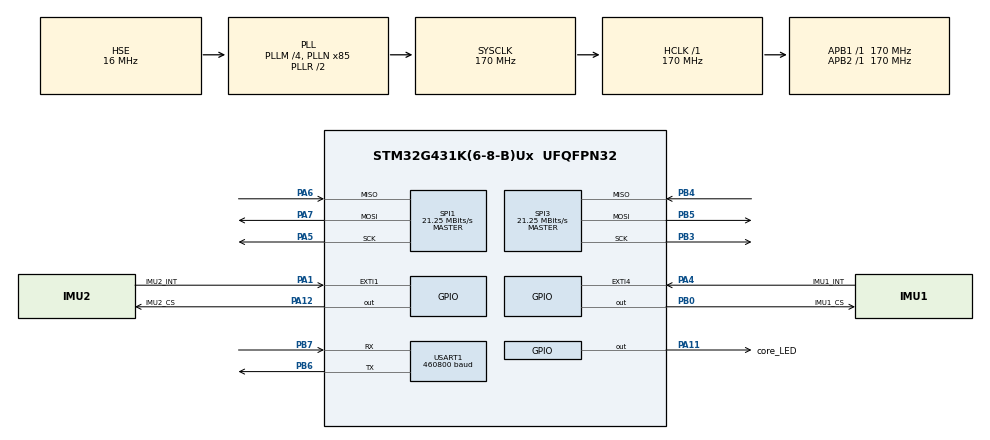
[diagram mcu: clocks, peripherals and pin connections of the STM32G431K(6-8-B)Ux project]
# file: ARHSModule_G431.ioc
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Dma.Request0=USART1_RX
Dma.Request1=USART1_TX
Dma.USART1_RX.0.Direction=DMA_PERIPH_TO_MEMORY
Dma.USART1_RX.0.EventEnable=DISABLE
Dma.USART1_RX.0.Instance=DMA1_Channel1
Dma.USART1_RX.0.MemDataAlignment=DMA_MDATAALIGN_BYTE
Dma.USART1_RX.0.MemInc=DMA_MINC_ENABLE
Dma.USART1_RX.0.Mode=DMA_NORMAL
Dma.USART1_RX.0.PeriphDataAlignment=DMA_PDATAALIGN_BYTE
Dma.USART1_RX.0.PeriphInc=DMA_PINC_DISABLE
Dma.USART1_RX.0.Polarity=HAL_DMAMUX_REQ_GEN_RISING
Dma.USART1_RX.0.Priority=DMA_PRIORITY_LOW
Dma.USART1_RX.0.RequestNumber=1
Dma.USART1_RX.0.SignalID=NONE
Dma.USART1_RX.0.SyncEnable=DISABLE
Dma.USART1_RX.0.SyncPolarity=HAL_DMAMUX_SYNC_NO_EVENT
Dma.USART1_RX.0.SyncRequestNumber=1
Dma.USART1_RX.0.SyncSignalID=NONE
Dma.USART1_TX.1.Direction=DMA_MEMORY_TO_PERIPH
Dma.USART1_TX.1.EventEnable=DISABLE
Dma.USART1_TX.1.Instance=DMA1_Channel2
Dma.USART1_TX.1.MemDataAlignment=DMA_MDATAALIGN_BYTE
Dma.USART1_TX.1.MemInc=DMA_MINC_ENABLE
Dma.USART1_TX.1.Mode=DMA_NORMAL
Dma.USART1_TX.1.PeriphDataAlignment=DMA_PDATAALIGN_BYTE
Dma.USART1_TX.1.PeriphInc=DMA_PINC_DISABLE
Dma.USART1_TX.1.Polarity=HAL_DMAMUX_REQ_GEN_RISING
Dma.USART1_TX.1.Priority=DMA_PRIORITY_HIGH
Dma.USART1_TX.1.RequestNumber=1
Dma.USART1_TX.1.SignalID=NONE
Dma.USART1_TX.1.SyncEnable=DISABLE
Dma.USART1_TX.1.SyncPolarity=HAL_DMAMUX_SYNC_NO_EVENT
Dma.USART1_TX.1.SyncRequestNumber=1
Dma.USART1_TX.1.SyncSignalID=NONE
Mcu.Family=STM32G4
Mcu.Name=STM32G431K(6-8-B)Ux
Mcu.Package=UFQFPN32
NVIC.DMA1_Channel1_IRQn=true\:5\:0\:true\:false\:true\:false\:true\:true
NVIC.DMA1_Channel2_IRQn=true\:5\:1\:true\:false\:true\:false\:true\:true
NVIC.EXTI4_IRQn=true\:0\:1\:false\:false\:true\:true\:true\:true
NVIC.PriorityGroup=NVIC_PRIORITYGROUP_3
NVIC.TIM1_UP_TIM16_IRQn=true\:0\:0\:false\:false\:true\:true\:true\:true
NVIC.USART1_IRQn=true\:3\:1\:true\:false\:true\:false\:true\:true
PA1.GPIO_Label=IMU2_INT
PA1.GPIO_PuPd=GPIO_PULLDOWN
PA1.Signal=GPXTI1
PA11.GPIO_Label=core_LED
PA11.GPIO_PuPd=GPIO_PULLUP
PA11.Signal=GPIO_Output
PA12.GPIO_Label=IMU2_CS
PA12.GPIO_PuPd=GPIO_NOPULL
PA12.PinState=GPIO_PIN_RESET
PA12.Signal=GPIO_Output
PA13.Mode=Serial_Wire
PA13.Signal=SYS_JTMS-SWDIO
PA14.Mode=Serial_Wire
PA14.Signal=SYS_JTCK-SWCLK
PA4.GPIO_Label=IMU1_INT
PA4.GPIO_PuPd=GPIO_PULLDOWN
PA4.Signal=GPXTI4
PA5.GPIO_Speed=GPIO_SPEED_FREQ_LOW
PA5.Mode=Full_Duplex_Master
PA5.Signal=SPI1_SCK
PA6.GPIO_Speed=GPIO_SPEED_FREQ_LOW
PA6.Mode=Full_Duplex_Master
PA6.Signal=SPI1_MISO
PA7.GPIO_Speed=GPIO_SPEED_FREQ_LOW
PA7.Mode=Full_Duplex_Master
PA7.Signal=SPI1_MOSI
PB0.GPIO_Label=IMU1_CS
PB0.GPIO_PuPd=GPIO_NOPULL
PB0.PinState=GPIO_PIN_RESET
PB0.Signal=GPIO_Output
PB3.GPIO_Speed=GPIO_SPEED_FREQ_VERY_HIGH
PB3.Mode=Full_Duplex_Master
PB3.Signal=SPI3_SCK
PB4.GPIO_Speed=GPIO_SPEED_FREQ_VERY_HIGH
PB4.Mode=Full_Duplex_Master
PB4.Signal=SPI3_MISO
PB5.GPIO_Speed=GPIO_SPEED_FREQ_VERY_HIGH
PB5.Mode=Full_Duplex_Master
PB5.Signal=SPI3_MOSI
PB6.Mode=Asynchronous
PB6.Signal=USART1_TX
PB7.Mode=Asynchronous
PB7.Signal=USART1_RX
PF0-OSC_IN.Mode=HSE-External-Oscillator
PF0-OSC_IN.Signal=RCC_OSC_IN
PF1-OSC_OUT.Mode=HSE-External-Oscillator
PF1-OSC_OUT.Signal=RCC_OSC_OUT
ProjectManager.HeapSize=0x2000
ProjectManager.StackSize=0x4000
ProjectManager.TargetToolchain=MDK-ARM V5.32
RCC.ADC12Freq_Value=170000000
RCC.AHBFreq_Value=170000000
RCC.APB1Freq_Value=170000000
RCC.APB1TimFreq_Value=170000000
RCC.APB2Freq_Value=170000000
RCC.APB2TimFreq_Value=170000000
RCC.CortexFreq_Value=170000000
RCC.EXTERNAL_CLOCK_VALUE=12288000
RCC.HCLKFreq_Value=170000000
RCC.HSE_VALUE=16000000
RCC.HSI48_VALUE=48000000
RCC.HSI_VALUE=16000000
RCC.LSE_VALUE=32768
RCC.PLLM=RCC_PLLM_DIV4
RCC.PLLN=85
RCC.PLLSourceVirtual=RCC_PLLSOURCE_HSE
RCC.SYSCLKFreq_VALUE=170000000
RCC.SYSCLKSource=RCC_SYSCLKSOURCE_PLLCLK
RCC.USBFreq_Value=170000000
RCC.VCOOutputFreq_Value=340000000
SPI1.BaudRatePrescaler=SPI_BAUDRATEPRESCALER_8
SPI1.CalculateBaudRate=21.25 MBits/s
SPI1.DataSize=SPI_DATASIZE_8BIT
SPI1.Direction=SPI_DIRECTION_2LINES
SPI1.Mode=SPI_MODE_MASTER
SPI1.NSSPMode=SPI_NSS_PULSE_DISABLE
SPI1.VirtualType=VM_MASTER
SPI3.BaudRatePrescaler=SPI_BAUDRATEPRESCALER_8
SPI3.CalculateBaudRate=21.25 MBits/s
SPI3.DataSize=SPI_DATASIZE_8BIT
SPI3.Direction=SPI_DIRECTION_2LINES
SPI3.Mode=SPI_MODE_MASTER
SPI3.NSSPMode=SPI_NSS_PULSE_DISABLE
SPI3.VirtualType=VM_MASTER
TIM1.PeriodNoDither=1000-1
TIM1.Prescaler=170-1
USART1.BaudRate=460800
USART1.VirtualMode-Asynchronous=VM_ASYNC
VP_SYS_VS_DBSignals.Mode=DisableDeadBatterySignals
VP_TIM1_VS_ClockSourceINT.Mode=Internal
board=custom

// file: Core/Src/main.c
/* USER CODE BEGIN Header */
/**
  ******************************************************************************
  * @file           : main.c
  * @brief          : Main program body
  ******************************************************************************
  * @attention
  *
  * Copyright (c) 2025 STMicroelectronics.
  * All rights reserved.
  *
  * This software is licensed under terms that can be found in the LICENSE file
  * in the root directory of this software component.
  * If no LICENSE file comes with this software, it is provided AS-IS.
  *
  ******************************************************************************
  */
/* USER CODE END Header */
#include "main.h"
#include "dma.h"
#include "spi.h"
#include "tim.h"
#include "usart.h"
#include "gpio.h"

/* USER CODE BEGIN Includes */
#include "delay.h"
#include "icm45686_task.h"
#include "angle.h"
/* USER CODE END Includes */

void SystemClock_Config(void);

int main(void)
{

  /* MCU Configuration--------------------------------------------------------*/

  /* Reset of all peripherals, Initializes the Flash interface and the Systick. */
  HAL_Init();

  /* Configure the system clock */
  SystemClock_Config();

  /* USER CODE BEGIN SysInit */
	delay_init(170);//基于内核时钟频率延时初始化
  /* USER CODE END SysInit */

  /* Initialize all configured peripherals */
  MX_GPIO_Init();
  MX_DMA_Init();
  MX_SPI1_Init();
  MX_SPI3_Init();
  MX_USART1_UART_Init();
  MX_TIM1_Init();
  /* USER CODE BEGIN 2 */
	LED(1);//点亮LED
	if(imu_init(&myIMU1) == INV_IMU_OK &&imu_init(&myIMU2) == INV_IMU_OK)
	{
		IMU_Calibration();//IMU静止状态下零漂矫正
		myIMU1.is_init_ok =1;
		myIMU2.is_init_ok =1;

	}
	else//错误 led闪烁50Hz
	{
		LED_TOGGLE;
		delay_ms(50);
	}

	HAL_TIM_Base_Start_IT(&htim1);
  /* USER CODE END 2 */

  /* Infinite loop */
  while (1)
  {

  }
}

void SystemClock_Config(void)
{
  RCC_OscInitTypeDef RCC_OscInitStruct = {0};
  RCC_ClkInitTypeDef RCC_ClkInitStruct = {0};

  /** Configure the main internal regulator output voltage
  */
  HAL_PWREx_ControlVoltageScaling(PWR_REGULATOR_VOLTAGE_SCALE1_BOOST);

  /** Initializes the RCC Oscillators according to the specified parameters
  * in the RCC_OscInitTypeDef structure.
  */
  RCC_OscInitStruct.OscillatorType = RCC_OSCILLATORTYPE_HSE;
  RCC_OscInitStruct.HSEState = RCC_HSE_ON;
  RCC_OscInitStruct.PLL.PLLState = RCC_PLL_ON;
  RCC_OscInitStruct.PLL.PLLSource = RCC_PLLSOURCE_HSE;
  RCC_OscInitStruct.PLL.PLLM = RCC_PLLM_DIV4;
  RCC_OscInitStruct.PLL.PLLN = 85;
  RCC_OscInitStruct.PLL.PLLP = RCC_PLLP_DIV2;
  RCC_OscInitStruct.PLL.PLLQ = RCC_PLLQ_DIV2;
  RCC_OscInitStruct.PLL.PLLR = RCC_PLLR_DIV2;
  if (HAL_RCC_OscConfig(&RCC_OscInitStruct) != HAL_OK)
  {
    Error_Handler();
  }

  /** Initializes the CPU, AHB and APB buses clocks
  */
  RCC_ClkInitStruct.ClockType = RCC_CLOCKTYPE_HCLK|RCC_CLOCKTYPE_SYSCLK
                              |RCC_CLOCKTYPE_PCLK1|RCC_CLOCKTYPE_PCLK2;
  RCC_ClkInitStruct.SYSCLKSource = RCC_SYSCLKSOURCE_PLLCLK;
  RCC_ClkInitStruct.AHBCLKDivider = RCC_SYSCLK_DIV1;
  RCC_ClkInitStruct.APB1CLKDivider = RCC_HCLK_DIV1;
  RCC_ClkInitStruct.APB2CLKDivider = RCC_HCLK_DIV1;

  if (HAL_RCC_ClockConfig(&RCC_ClkInitStruct, FLASH_LATENCY_4) != HAL_OK)
  {
    Error_Handler();
  }
}

void Error_Handler(void)
{
  __disable_irq();
  while (1)
  {
  }
}
